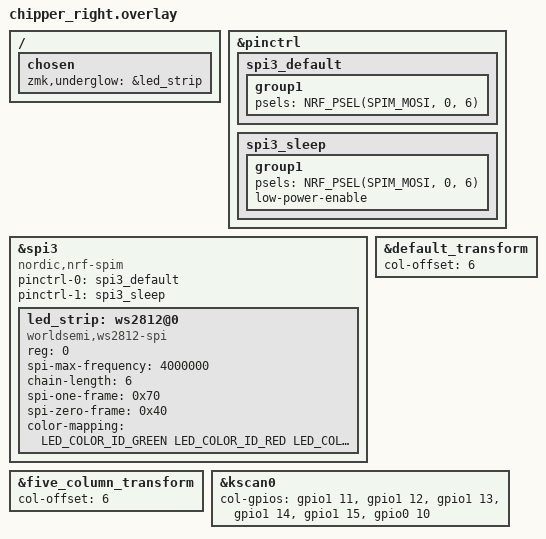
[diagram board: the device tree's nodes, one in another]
#include <dt-bindings/led/led.h>

#include "chipper.dtsi"

&pinctrl {
  spi3_default: spi3_default {
    group1 {
      psels = <NRF_PSEL(SPIM_MOSI, 0, 6)>;
    };
  };

  spi3_sleep: spi3_sleep {
    group1 {
      psels = <NRF_PSEL(SPIM_MOSI, 0, 6)>;
      low-power-enable;
    };
  };
};

&spi3 {
  compatible = "nordic,nrf-spim";
  status = "okay";

  pinctrl-0 = <&spi3_default>;
  pinctrl-1 = <&spi3_sleep>;
  pinctrl-names = "default", "sleep";

  led_strip: ws2812@0 {
    compatible = "worldsemi,ws2812-spi";
    reg = <0>;
    spi-max-frequency = <4000000>;
    chain-length = <6>;
    spi-one-frame = <0x70>;
    spi-zero-frame = <0x40>;
    color-mapping = <LED_COLOR_ID_GREEN LED_COLOR_ID_RED LED_COLOR_ID_BLUE>;
  };
};

/ {
  chosen {
    zmk,underglow = &led_strip;
  };
};

&default_transform {
  col-offset = <6>;
};

&five_column_transform {
  col-offset = <6>;
};

&kscan0 {
  col-gpios
    = <&gpio1 11 GPIO_ACTIVE_HIGH> //Col0
    , <&gpio1 12 GPIO_ACTIVE_HIGH>  //Col1
    , <&gpio1 13 GPIO_ACTIVE_HIGH>  //Col2
    , <&gpio1 14 GPIO_ACTIVE_HIGH>  //Col3
    , <&gpio1 15 GPIO_ACTIVE_HIGH>  //Col4
    , <&gpio0 10 GPIO_ACTIVE_HIGH>  //Col5
    ;
};
